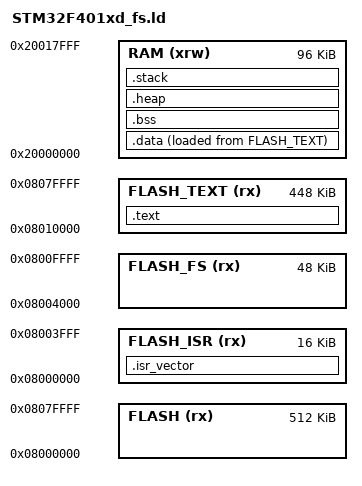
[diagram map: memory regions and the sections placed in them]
/*
    GNU linker script for STM32F401 with bootloader (such as the Meowbit)
*/

/* Specify the memory areas */
MEMORY
{
    FLASH (rx)      : ORIGIN = 0x08000000, LENGTH = 512K /* entire flash */
    FLASH_ISR (rx)  : ORIGIN = 0x08000000, LENGTH = 16K /* sector 0 */
    FLASH_FS (rx)   : ORIGIN = 0x08004000, LENGTH = 48K /* sectors 1,2,3 are 16K */
    FLASH_TEXT (rx) : ORIGIN = 0x08010000, LENGTH = 448K /* sector 4 is 64K, sectors 5,6,7 are 128K */
    RAM (xrw)       : ORIGIN = 0x20000000, LENGTH = 96K
}

/* produce a link error if there is not this amount of RAM for these sections */
_minimum_stack_size = 2K;
_minimum_heap_size = 16K;

/* Define tho top end of the stack.  The stack is full descending so begins just
   above last byte of RAM.  Note that EABI requires the stack to be 8-byte
   aligned for a call. */
_estack = ORIGIN(RAM) + LENGTH(RAM);

/* RAM extents for the garbage collector */
_ram_start = ORIGIN(RAM);
_ram_end = ORIGIN(RAM) + LENGTH(RAM);

ENTRY(Reset_Handler)

/* define output sections */
SECTIONS
{
    /* The startup code goes first into FLASH */
    .isr_vector :
    {
        . = ALIGN(4);
        KEEP(*(.isr_vector)) /* Startup code */

        /* This first flash block is 16K annd the isr vectors only take up
           about 400 bytes. Micropython pads this with files, but this didn't
           work with the size of Circuitpython's ff object. */

        . = ALIGN(4);
    } >FLASH_ISR

    /* The program code and other data goes into FLASH */
    .text :
    {
        . = ALIGN(4);
        *(.text*)          /* .text* sections (code) */
        *(.rodata*)        /* .rodata* sections (constants, strings, etc.) */
    /*  *(.glue_7)   */    /* glue arm to thumb code */
    /*  *(.glue_7t)  */    /* glue thumb to arm code */

        . = ALIGN(4);
        _etext = .;        /* define a global symbol at end of code */
    } >FLASH_TEXT

    /* used by the startup to initialize data */
    _sidata = LOADADDR(.data);

    /* This is the initialized data section
    The program executes knowing that the data is in the RAM
    but the loader puts the initial values in the FLASH (inidata).
    It is one task of the startup to copy the initial values from FLASH to RAM. */
    .data :
    {
        . = ALIGN(4);
        _sdata = .;        /* create a global symbol at data start; used by startup code in order to initialise the .data section in RAM */
        *(.data*)          /* .data* sections */

        . = ALIGN(4);
        _edata = .;        /* define a global symbol at data end; used by startup code in order to initialise the .data section in RAM */
    } >RAM AT> FLASH_TEXT

    /* Uninitialized data section */
    .bss :
    {
        . = ALIGN(4);
        _sbss = .;         /* define a global symbol at bss start; used by startup code */
        *(.bss*)
        *(COMMON)

        . = ALIGN(4);
        _ebss = .;         /* define a global symbol at bss end; used by startup code and GC */
    } >RAM

    /* this is to define the start of the heap, and make sure we have a minimum size */
    .heap :
    {
        . = ALIGN(4);
        . = . + _minimum_heap_size;
        . = ALIGN(4);
    } >RAM

    /* this just checks there is enough RAM for the stack */
    .stack :
    {
        . = ALIGN(4);
        . = . + _minimum_stack_size;
        . = ALIGN(4);
    } >RAM

    .ARM.attributes 0 : { *(.ARM.attributes) }
}


